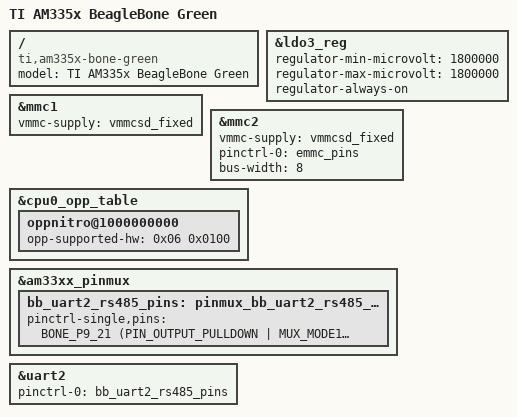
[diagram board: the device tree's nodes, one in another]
/*
 * Copyright (C) 2012 Texas Instruments Incorporated - http://www.ti.com/
 *
 * This program is free software; you can redistribute it and/or modify
 * it under the terms of the GNU General Public License version 2 as
 * published by the Free Software Foundation.
 */
/dts-v1/;

#include "am33xx.dtsi"
#include "am335x-bone-common.dtsi"
#include <dt-bindings/board/am335x-bbw-bbb-base.h>
/* #include "am33xx-overlay-edma-fix.dtsi" */

/* pruss: pick one: */

/*
 * /etc/modprobe.d/pruss-blacklist.conf
 *
 * blacklist uio_pruss
 */

/* #include "am33xx-pruss-rproc.dtsi" */

/*
 * /etc/modprobe.d/pruss-blacklist.conf
 *
 * blacklist pruss
 * blacklist pruss_intc
 * blacklist pru-rproc
 */

/* #include "am33xx-pruss-uio.dtsi" */

/ {
	model = "TI AM335x BeagleBone Green";
	compatible = "ti,am335x-bone-green", "ti,am335x-bone-black", "ti,am335x-bone", "ti,am33xx";
};

&ldo3_reg {
	regulator-min-microvolt = <1800000>;
	regulator-max-microvolt = <1800000>;
	regulator-always-on;
};

&mmc1 {
	vmmc-supply = <&vmmcsd_fixed>;
};

&mmc2 {
	vmmc-supply = <&vmmcsd_fixed>;
	pinctrl-names = "default";
	pinctrl-0 = <&emmc_pins>;
	bus-width = <8>;
	status = "okay";
};

&cpu0_opp_table {
	/*
	 * All PG 2.0 silicon may not support 1GHz but some of the early
	 * BeagleBone Blacks have PG 2.0 silicon which is guaranteed
	 * to support 1GHz OPP so enable it for PG 2.0 on this board.
	 */
	oppnitro@1000000000 {
		opp-supported-hw = <0x06 0x0100>;
	};
};

&am33xx_pinmux {
    bb_uart2_rs485_pins: pinmux_bb_uart2_rs485_pins {
        pinctrl-single,pins = <
            /* P9_21: spi0_d0.uart2_txd */
            BONE_P9_21 (PIN_OUTPUT_PULLDOWN | MUX_MODE1)
            /* P9_22: spi0_sclk.uart2_rxd */
            BONE_P9_22 (PIN_INPUT_PULLUP | MUX_MODE1)
            BONE_P8_38 (PIN_OUTPUT_PULLDOWN | MUX_MODE6)
        >;
    };
};

&uart2 {
    status = "okay";
    pinctrl-names = "default";
    pinctrl-0 = <&bb_uart2_rs485_pins>;
};
